# MKL28T7_CORE1 register map
Vendor: Freescale Semiconductor, Inc.; Series: Kinetis_L; File version: 1.6
CPU: CM0PLUS r0p0, little endian, no MPU, no FPU, VTOR, 2 interrupt priority bits
Registers are 32-bit, read-write, reset 0x0 unless marked. A register's access mark holds for its fields unless they carry their own. Offsets are from the block's base; [hi:lo] are bit positions; 'fields as' and 'values as' point back to an identical list.

## LPI2C0 — The LPI2C Memory Map/Register Definition can be found here.
Base 0x400C0000; register names take the prefix LPI2C0_
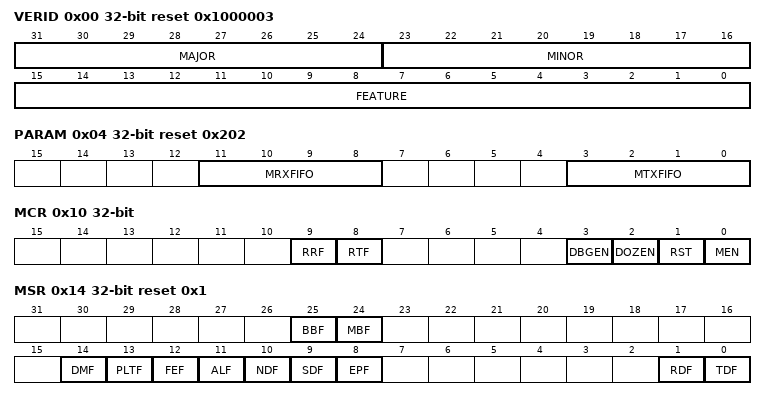
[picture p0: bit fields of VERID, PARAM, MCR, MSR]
0x00 VERID ro reset 0x1000003 — Version ID Register
  [31:24] MAJOR — Major Version Number
  [23:16] MINOR — Minor Version Number
  [15:0] FEATURE — Feature Specification Number
    2=Master only with standard feature set; 3=Master and slave with standard feature set
0x04 PARAM ro reset 0x202 — Parameter Register
  [11:8] MRXFIFO — Master Receive FIFO Size
  [3:0] MTXFIFO — Master Transmit FIFO Size
0x10 MCR — Master Control Register
  [9] RRF wo — Reset Receive FIFO
    0=No effect; 1=Receive FIFO is reset
  [8] RTF wo — Reset Transmit FIFO
    0=No effect; 1=Transmit FIFO is reset
  [3] DBGEN — Debug Enable
    0=Master is disabled in debug mode; 1=Master is enabled in debug mode
  [2] DOZEN — Doze mode enable
    0=Master is enabled in Doze mode; 1=Master is disabled in Doze mode
  [1] RST — Software Reset
    0=Master logic is not reset; 1=Master logic is reset
  [0] MEN — Master Enable
    0=Master logic is disabled; 1=Master logic is enabled
0x14 MSR reset 0x1 — Master Status Register
  [25] BBF ro — Bus Busy Flag
    0=I2C Bus is idle; 1=I2C Bus is busy
  [24] MBF ro — Master Busy Flag
    0=I2C Master is idle; 1=I2C Master is busy
  [14] DMF — Data Match Flag
    0=Have not received matching data; 1=Have received matching data
  [13] PLTF — Pin Low Timeout Flag
    0=Pin low timeout has not occurred or is disabled; 1=Pin low timeout has occurred
  [12] FEF — FIFO Error Flag
    0=No error; 1=Master sending or receiving data without START condition
  [11] ALF — Arbitration Lost Flag
    0=Master has not lost arbitration; 1=Master has lost arbitration
  [10] NDF — NACK Detect Flag
    0=Unexpected NACK not detected; 1=Unexpected NACK was detected
  [9] SDF — STOP Detect Flag
    0=Master has not generated a STOP condition; 1=Master has generated a STOP condition
  [8] EPF — End Packet Flag
    0=Master has not generated a STOP or Repeated START condition; 1=Master has generated a STOP or Repeated START condition
  [1] RDF ro — Receive Data Flag
    0=Receive Data is not ready; 1=Receive data is ready
  [0] TDF ro — Transmit Data Flag
    0=Transmit data not requested; 1=Transmit data is requested
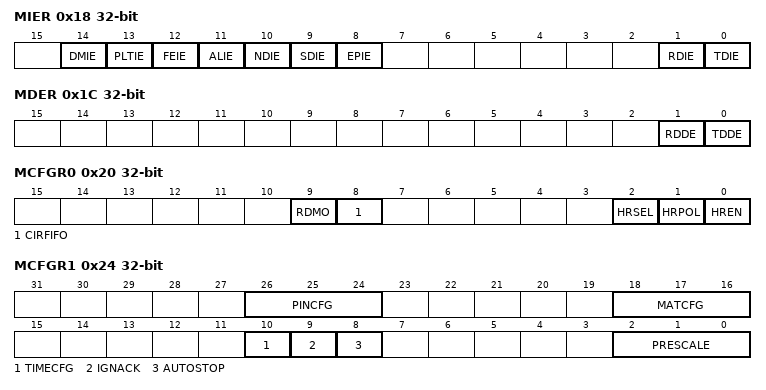
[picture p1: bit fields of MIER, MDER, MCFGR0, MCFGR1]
0x18 MIER — Master Interrupt Enable Register
  [14] DMIE — Data Match Interrupt Enable
    0=Interrupt disabled; 1=Interrupt enabled
  [13] PLTIE — Pin Low Timeout Interrupt Enable
    0=Interrupt disabled; 1=Interrupt enabled
  [12] FEIE — FIFO Error Interrupt Enable
    0=Interrupt enabled; 1=Interrupt disabled
  [11] ALIE — Arbitration Lost Interrupt Enable
    0=Interrupt disabled; 1=Interrupt enabled
  [10] NDIE — NACK Detect Interrupt Enable
    0=Interrupt disabled; 1=Interrupt enabled
  [9] SDIE — STOP Detect Interrupt Enable
    0=Interrupt disabled; 1=Interrupt enabled
  [8] EPIE — End Packet Interrupt Enable
    0=Interrupt disabled; 1=Interrupt enabled
  [1] RDIE — Receive Data Interrupt Enable
    0=Interrupt disabled; 1=Interrupt enabled
  [0] TDIE — Transmit Data Interrupt Enable
    0=Interrupt disabled; 1=Interrupt enabled
0x1C MDER — Master DMA Enable Register
  [1] RDDE — Receive Data DMA Enable
    0=DMA request disabled; 1=DMA request enabled
  [0] TDDE — Transmit Data DMA Enable
    0=DMA request disabled; 1=DMA request enabled
0x20 MCFGR0 — Master Configuration Register 0
  [9] RDMO — Receive Data Match Only
    0=Received data is stored in the receive FIFO as normal; 1=Received data is discarded unless the RMF is set
  [8] CIRFIFO — Circular FIFO Enable
    0=Circular FIFO is disabled; 1=Circular FIFO is enabled
  [2] HRSEL — Host Request Select
    0=Host request input is pin LPI2C_HREQ; 1=Host request input is input trigger
  [1] HRPOL — Host Request Polarity
    0=Active low; 1=Active high
  [0] HREN — Host Request Enable
    0=Host request input is disabled; 1=Host request input is enabled
0x24 MCFGR1 — Master Configuration Register 1
  [26:24] PINCFG — Pin Configuration
    0=LPI2C configured for 2-pin open drain mode; 1=LPI2C configured for 2-pin output only mode (ultra-fast mode); 2=LPI2C configured for 2-pin push-pull mode; 3=LPI2C configured for 4-pin push-pull mode; 4=LPI2C configured for 2-pin open drain mode with separate LPI2C slave; 5=LPI2C configured for 2-pin output only mode (ultra-fast mode) with separate LPI2C slave; 6=LPI2C configured for 2-pin push-pull mode with separate LPI2C slave; 7=LPI2C configured for 4-pin push-pull mode (inverted outputs)
  [18:16] MATCFG — Match Configuration
    0=Match disabled; 2=Match enabled (1st data word equals MATCH0 OR MATCH1); 3=Match enabled (any data word equals MATCH0 OR MATCH1); 4=Match enabled (1st data word equals MATCH0 AND 2nd data word equals MATCH1); 5=Match enabled (any data word equals MATCH0 AND next data word equals MATCH1); 6=Match enabled (1st data word AND MATCH1 equals MATCH0 AND MATCH1); 7=Match enabled (any data word AND MATCH1 equals MATCH0 AND MATCH1)
  [10] TIMECFG — Timeout Configuration
    0=Pin Low Timeout Flag will set if SCL is low for longer than the configured timeout; 1=Pin Low Timeout Flag will set if either SCL or SDA is low for longer than the configured timeout
  [9] IGNACK — When set, the received NACK field is ignored and assumed to be ACK
    0=LPI2C Master will receive ACK and NACK normally; 1=LPI2C Master will treat a received NACK as if it was an ACK
  [8] AUTOSTOP — Automatic STOP Generation
    0=No effect; 1=STOP condition is automatically generated whenever the transmit FIFO is empty and LPI2C master is busy
  [2:0] PRESCALE — Prescaler
    0=Divide by 1; 1=Divide by 2; 2=Divide by 4; 3=Divide by 8; 4=Divide by 16; 5=Divide by 32; 6=Divide by 64; 7=Divide by 128
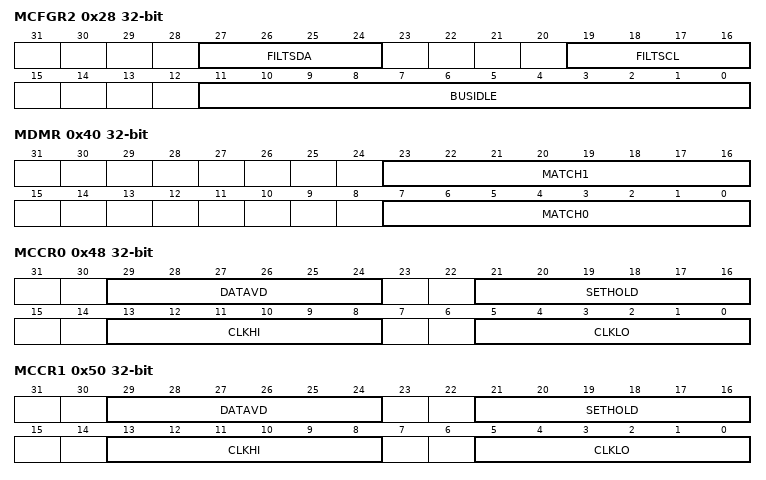
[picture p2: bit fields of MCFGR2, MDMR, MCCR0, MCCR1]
0x28 MCFGR2 — Master Configuration Register 2
  [27:24] FILTSDA — Glitch Filter SDA
  [19:16] FILTSCL — Glitch Filter SCL
  [11:0] BUSIDLE — Bus Idle Timeout
0x2C MCFGR3 — Master Configuration Register 3
  [19:8] PINLOW — Pin Low Timeout
0x40 MDMR — Master Data Match Register
  [23:16] MATCH1 — Match 1 Value
  [7:0] MATCH0 — Match 0 Value
0x48 MCCR0 — Master Clock Configuration Register 0
  [29:24] DATAVD — Data Valid Delay
  [21:16] SETHOLD — Setup Hold Delay
  [13:8] CLKHI — Clock High Period
  [5:0] CLKLO — Clock Low Period
0x50 MCCR1 — Master Clock Configuration Register 1
  fields as MCCR0
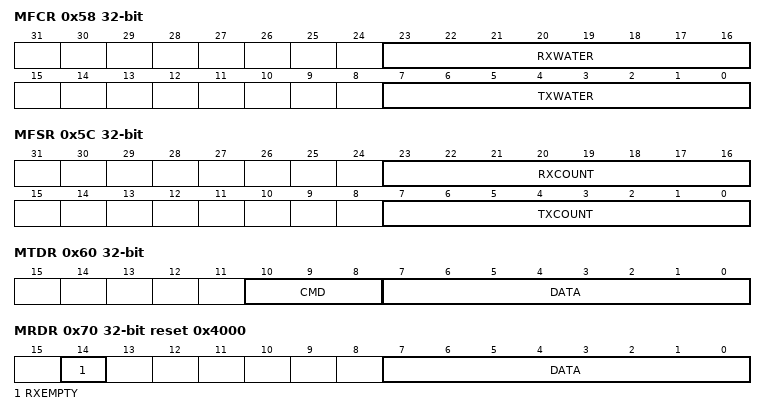
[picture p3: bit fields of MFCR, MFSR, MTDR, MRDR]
0x58 MFCR — Master FIFO Control Register
  [23:16] RXWATER — Receive FIFO Watermark
  [7:0] TXWATER — Transmit FIFO Watermark
0x5C MFSR ro — Master FIFO Status Register
  [23:16] RXCOUNT — Receive FIFO Count
  [7:0] TXCOUNT — Transmit FIFO Count
0x60 MTDR wo — Master Transmit Data Register
  [10:8] CMD — Command Data
    0=Transmit DATA[7:0]; 1=Receive (DATA[7:0] + 1) bytes; 2=Generate STOP condition; 3=Receive and discard (DATA[7:0] + 1) bytes; 4=Generate (repeated) START and transmit address in DATA[7:0]; 5=Generate (repeated) START and transmit address in DATA[7:0]. This transfer expects a NACK to be returned.; 6=Generate (repeated) START and transmit address in DATA[7:0] using high speed mode; 7=Generate (repeated) START and transmit address in DATA[7:0] using high speed mode. This transfer expects a NACK to be returned.
  [7:0] DATA — Transmit Data
0x70 MRDR ro reset 0x4000 — Master Receive Data Register
  [14] RXEMPTY
    0=Receive FIFO is not empty; 1=Receive FIFO is empty
  [7:0] DATA — Receive Data
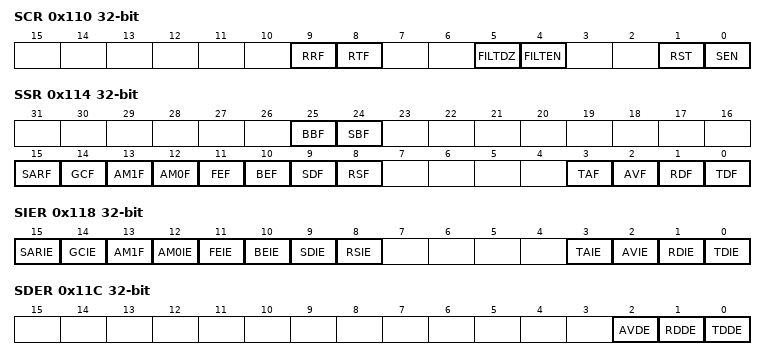
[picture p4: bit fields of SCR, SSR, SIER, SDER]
0x110 SCR — Slave Control Register
  [9] RRF wo — Reset Receive FIFO
    0=No effect; 1=Receive Data Register is now empty
  [8] RTF wo — Reset Transmit FIFO
    0=No effect; 1=Transmit Data Register is now empty
  [5] FILTDZ — Filter Doze Enable
    0=Filter remains enabled in Doze mode; 1=Filter is disabled in Doze mode
  [4] FILTEN — Filter Enable
    0=Disable digital filter and output delay counter for slave mode; 1=Enable digital filter and output delay counter for slave mode
  [1] RST — Software Reset
    0=Slave logic is not reset; 1=Slave logic is reset
  [0] SEN — Slave Enable
    0=Slave mode is disabled; 1=Slave mode is enabled
0x114 SSR — Slave Status Register
  [25] BBF ro — Bus Busy Flag
    0=I2C Bus is idle; 1=I2C Bus is busy
  [24] SBF ro — Slave Busy Flag
    0=I2C Slave is idle; 1=I2C Slave is busy
  [15] SARF ro — SMBus Alert Response Flag
    0=SMBus Alert Response disabled or not detected; 1=SMBus Alert Response enabled and detected
  [14] GCF ro — General Call Flag
    0=Slave has not detected the General Call Address or General Call Address disabled; 1=Slave has detected the General Call Address
  [13] AM1F ro — Address Match 1 Flag
    0=Have not received ADDR1 or ADDR0/ADDR1 range matching address; 1=Have received ADDR1 or ADDR0/ADDR1 range matching address
  [12] AM0F ro — Address Match 0 Flag
    0=Have not received ADDR0 matching address; 1=Have received ADDR0 matching address
  [11] FEF — FIFO Error Flag
    0=FIFO underflow or overflow not detected; 1=FIFO underflow or overflow detected
  [10] BEF — Bit Error Flag
    0=Slave has not detected a bit error; 1=Slave has detected a bit error
  [9] SDF — STOP Detect Flag
    0=Slave has not detected a STOP condition; 1=Slave has detected a STOP condition
  [8] RSF — Repeated Start Flag
    0=Slave has not detected a Repeated START condition; 1=Slave has detected a Repeated START condition
  [3] TAF ro — Transmit ACK Flag
    0=Transmit ACK/NACK is not required; 1=Transmit ACK/NACK is required
  [2] AVF ro — Address Valid Flag
    0=Address Status Register is not valid; 1=Address Status Register is valid
  [1] RDF ro — Receive Data Flag
    0=Receive Data is not ready; 1=Receive data is ready
  [0] TDF ro — Transmit Data Flag
    0=Transmit data not requested; 1=Transmit data is requested
0x118 SIER — Slave Interrupt Enable Register
  [15] SARIE — SMBus Alert Response Interrupt Enable
    0=Interrupt disabled; 1=Interrupt enabled
  [14] GCIE — General Call Interrupt Enable
    0=Interrupt disabled; 1=Interrupt enabled
  [13] AM1F — Address Match 1 Interrupt Enable
    0=Interrupt disabled; 1=Interrupt enabled
  [12] AM0IE — Address Match 0 Interrupt Enable
    0=Interrupt enabled; 1=Interrupt disabled
  [11] FEIE — FIFO Error Interrupt Enable
    0=Interrupt disabled; 1=Interrupt enabled
  [10] BEIE — Bit Error Interrupt Enable
    0=Interrupt disabled; 1=Interrupt enabled
  [9] SDIE — STOP Detect Interrupt Enable
    0=Interrupt disabled; 1=Interrupt enabled
  [8] RSIE — Repeated Start Interrupt Enable
    0=Interrupt disabled; 1=Interrupt enabled
  [3] TAIE — Transmit ACK Interrupt Enable
    0=Interrupt disabled; 1=Interrupt enabled
  [2] AVIE — Address Valid Interrupt Enable
    0=Interrupt disabled; 1=Interrupt enabled
  [1] RDIE — Receive Data Interrupt Enable
    0=Interrupt disabled; 1=Interrupt enabled
  [0] TDIE — Transmit Data Interrupt Enable
    0=Interrupt disabled; 1=Interrupt enabled
0x11C SDER — Slave DMA Enable Register
  [all] fields
    0=DMA request disabled; 1=DMA request enabled
  [2] AVDE — Address Valid DMA Enable
  [1] RDDE — Receive Data DMA Enable
  [0] TDDE — Transmit Data DMA Enable
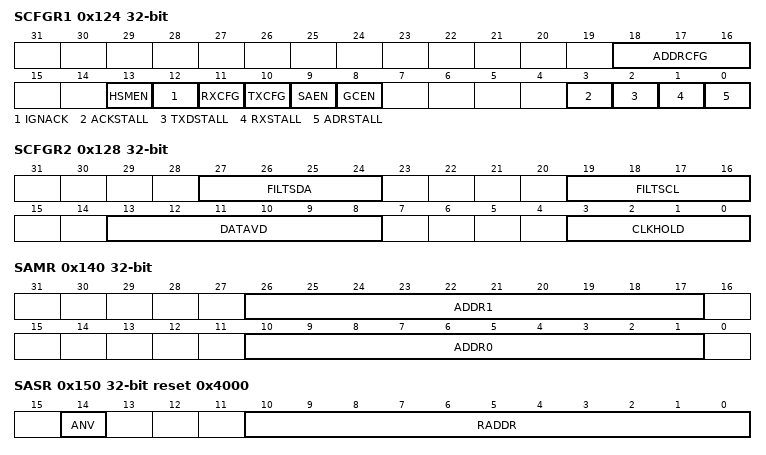
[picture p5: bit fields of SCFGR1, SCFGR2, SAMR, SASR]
0x124 SCFGR1 — Slave Configuration Register 1
  [18:16] ADDRCFG — Address Configuration
    0=Address match 0 (7-bit); 1=Address match 0 (10-bit); 2=Address match 0 (7-bit) or Address match 1 (7-bit); 3=Address match 0 (10-bit) or Address match 1 (10-bit); 4=Address match 0 (7-bit) or Address match 1 (10-bit); 5=Address match 0 (10-bit) or Address match 1 (7-bit); 6=From Address match 0 (7-bit) to Address match 1 (7-bit); 7=From Address match 0 (10-bit) to Address match 1 (10-bit)
  [13] HSMEN — High Speed Mode Enable
    0=Disables detection of Hs-mode master code; 1=Enables detection of Hs-mode master code
  [12] IGNACK — Ignore NACK
    0=Slave will end transfer when NACK detected; 1=Slave will not end transfer when NACK detected
  [11] RXCFG — Receive Data Configuration
    0=Reading the receive data register will return receive data and clear the receive data flag; 1=Reading the receive data register when the address valid flag is set will return the address status register and clear the address valid flag. Reading the receive data register when the address valid flag is clear will return receive data and clear the receive data flag.
  [10] TXCFG — Transmit Flag Configuration
    0=Transmit Data Flag will only assert during a slave-transmit transfer when the transmit data register is empty; 1=Transmit Data Flag will assert whenever the transmit data register is empty
  [9] SAEN — SMBus Alert Enable
    0=Disables match on SMBus Alert; 1=Enables match on SMBus Alert
  [8] GCEN — General Call Enable
    0=General Call address is disabled; 1=General call address is enabled
  [3] ACKSTALL — ACK SCL Stall
    0=Clock stretching disabled; 1=Clock stretching enabled
  [2] TXDSTALL — TX Data SCL Stall
    0=Clock stretching disabled; 1=Clock stretching enabled
  [1] RXSTALL — RX SCL Stall
    0=Clock stretching disabled; 1=Clock stretching enabled
  [0] ADRSTALL — Address SCL Stall
    0=Clock stretching disabled; 1=Clock stretching enabled
0x128 SCFGR2 — Slave Configuration Register 2
  [27:24] FILTSDA — Glitch Filter SDA
  [19:16] FILTSCL — Glitch Filter SCL
  [13:8] DATAVD — Data Valid Delay
  [3:0] CLKHOLD — Clock Hold Time
0x140 SAMR — Slave Address Match Register
  [26:17] ADDR1 — Address 1 Value
  [10:1] ADDR0 — Address 0 Value
0x150 SASR ro reset 0x4000 — Slave Address Status Register
  [14] ANV — Address Not Valid
    0=RADDR is valid; 1=RADDR is not valid
  [10:0] RADDR — Received Address
0x154 STAR — Slave Transmit ACK Register
  [0] TXNACK — Transmit NACK
    0=Transmit ACK for received word; 1=Transmit NACK for received word
0x160 STDR wo — Slave Transmit Data Register
  [7:0] DATA — Transmit Data
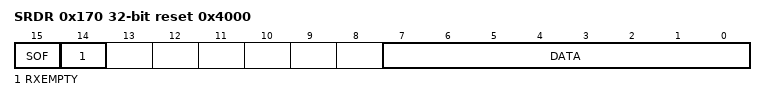
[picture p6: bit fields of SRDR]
0x170 SRDR ro reset 0x4000 — Slave Receive Data Register
  [15] SOF — Start Of Frame
    0=Indicates this is not the first data word since a (repeated) START or STOP condition; 1=Indicates this is the first data word since a (repeated) START or STOP condition
  [14] RXEMPTY
    0=The Receive Data Register is not empty; 1=The Receive Data Register is empty
  [7:0] DATA — Receive Data

## LPI2C1 — The LPI2C Memory Map/Register Definition can be found here.
Base 0x400C1000; register names take the prefix LPI2C1_
Registers as LPI2C0.

## LPI2C2 — The LPI2C Memory Map/Register Definition can be found here.
Base 0x40042000; register names take the prefix LPI2C2_
Registers as LPI2C0.
